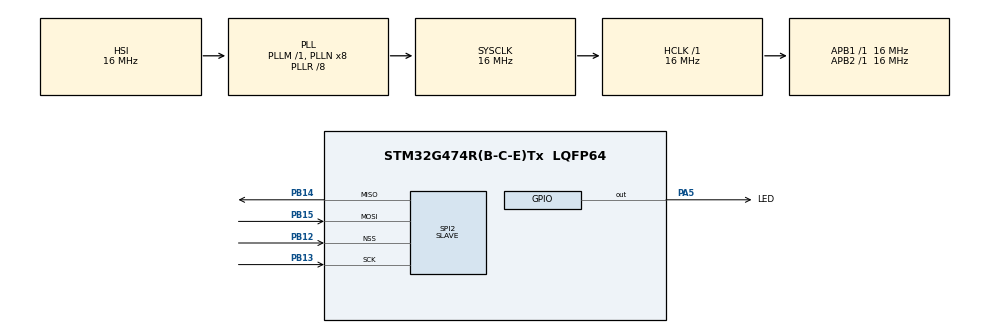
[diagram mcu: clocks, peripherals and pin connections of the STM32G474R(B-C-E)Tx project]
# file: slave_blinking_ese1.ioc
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Mcu.Family=STM32G4
Mcu.Name=STM32G474R(B-C-E)Tx
Mcu.Package=LQFP64
NVIC.PriorityGroup=NVIC_PRIORITYGROUP_4
PA5.GPIO_Label=LED
PA5.Signal=GPIO_Output
PB12.Mode=NSS_Signal_Hard_Input
PB12.Signal=SPI2_NSS
PB13.Mode=Full_Duplex_Slave
PB13.Signal=SPI2_SCK
PB14.Mode=Full_Duplex_Slave
PB14.Signal=SPI2_MISO
PB15.Mode=Full_Duplex_Slave
PB15.Signal=SPI2_MOSI
ProjectManager.HeapSize=0x200
ProjectManager.StackSize=0x400
ProjectManager.TargetToolchain=STM32CubeIDE
RCC.ADC12Freq_Value=16000000
RCC.ADC345Freq_Value=16000000
RCC.AHBFreq_Value=16000000
RCC.APB1Freq_Value=16000000
RCC.APB1TimFreq_Value=16000000
RCC.APB2Freq_Value=16000000
RCC.APB2TimFreq_Value=16000000
RCC.CortexFreq_Value=16000000
RCC.EXTERNAL_CLOCK_VALUE=12288000
RCC.HCLKFreq_Value=16000000
RCC.HSE_VALUE=24000000
RCC.HSI48_VALUE=48000000
RCC.HSI_VALUE=16000000
RCC.LSE_VALUE=32768
RCC.PLLR=RCC_PLLR_DIV8
RCC.RTCClockSelection=RCC_RTCCLKSOURCE_LSE
RCC.SYSCLKFreq_VALUE=16000000
RCC.SYSCLKSource=RCC_SYSCLKSOURCE_PLLCLK
RCC.USBFreq_Value=64000000
RCC.VCOOutputFreq_Value=128000000
SPI2.DataSize=SPI_DATASIZE_8BIT
SPI2.Direction=SPI_DIRECTION_2LINES
SPI2.Mode=SPI_MODE_SLAVE
SPI2.VirtualNSS=VM_NSSHARD
SPI2.VirtualType=VM_SLAVE
VP_SYS_VS_DBSignals.Mode=DisableDeadBatterySignals
board=NUCLEO-G474RE

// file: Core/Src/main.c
/* USER CODE BEGIN Header */
/**
  ******************************************************************************
  * @file           : main.c
  * @brief          : Main program body
  ******************************************************************************
  * @attention
  *
  * Copyright (c) 2026 STMicroelectronics.
  * All rights reserved.
  *
  * This software is licensed under terms that can be found in the LICENSE file
  * in the root directory of this software component.
  * If no LICENSE file comes with this software, it is provided AS-IS.
  *
  ******************************************************************************
  */
/* USER CODE END Header */
#include "main.h"
#include "spi.h"
#include "gpio.h"

void SystemClock_Config(void);

int main(void)
{

  /* USER CODE BEGIN 1 */
	uint8_t rx_msg=0;
  /* USER CODE END 1 */

  /* MCU Configuration--------------------------------------------------------*/

  /* Reset of all peripherals, Initializes the Flash interface and the Systick. */
  HAL_Init();

  /* Configure the system clock */
  SystemClock_Config();

  /* Initialize all configured peripherals */
  MX_GPIO_Init();
  MX_SPI2_Init();

  /* Infinite loop */
  while (1)
  {

    /* USER CODE BEGIN 3 */
	  HAL_SPI_Receive(&hspi2, &rx_msg, 1, HAL_MAX_DELAY);

	  switch(rx_msg){
	  case 0:
		  HAL_GPIO_WritePin(GPIOA, GPIO_PIN_5, GPIO_PIN_RESET);

		  break;
	  case 1:
		HAL_GPIO_WritePin(GPIOA, GPIO_PIN_5, GPIO_PIN_SET);
			break;
	  }

  }
  /* USER CODE END 3 */
}

void SystemClock_Config(void)
{
  RCC_OscInitTypeDef RCC_OscInitStruct = {0};
  RCC_ClkInitTypeDef RCC_ClkInitStruct = {0};

  /** Configure the main internal regulator output voltage
  */
  HAL_PWREx_ControlVoltageScaling(PWR_REGULATOR_VOLTAGE_SCALE1);

  /** Initializes the RCC Oscillators according to the specified parameters
  * in the RCC_OscInitTypeDef structure.
  */
  RCC_OscInitStruct.OscillatorType = RCC_OSCILLATORTYPE_HSI;
  RCC_OscInitStruct.HSIState = RCC_HSI_ON;
  RCC_OscInitStruct.HSICalibrationValue = RCC_HSICALIBRATION_DEFAULT;
  RCC_OscInitStruct.PLL.PLLState = RCC_PLL_ON;
  RCC_OscInitStruct.PLL.PLLSource = RCC_PLLSOURCE_HSI;
  RCC_OscInitStruct.PLL.PLLM = RCC_PLLM_DIV1;
  RCC_OscInitStruct.PLL.PLLN = 8;
  RCC_OscInitStruct.PLL.PLLP = RCC_PLLP_DIV2;
  RCC_OscInitStruct.PLL.PLLQ = RCC_PLLQ_DIV2;
  RCC_OscInitStruct.PLL.PLLR = RCC_PLLR_DIV8;
  if (HAL_RCC_OscConfig(&RCC_OscInitStruct) != HAL_OK)
  {
    Error_Handler();
  }

  /** Initializes the CPU, AHB and APB buses clocks
  */
  RCC_ClkInitStruct.ClockType = RCC_CLOCKTYPE_HCLK|RCC_CLOCKTYPE_SYSCLK
                              |RCC_CLOCKTYPE_PCLK1|RCC_CLOCKTYPE_PCLK2;
  RCC_ClkInitStruct.SYSCLKSource = RCC_SYSCLKSOURCE_PLLCLK;
  RCC_ClkInitStruct.AHBCLKDivider = RCC_SYSCLK_DIV1;
  RCC_ClkInitStruct.APB1CLKDivider = RCC_HCLK_DIV1;
  RCC_ClkInitStruct.APB2CLKDivider = RCC_HCLK_DIV1;

  if (HAL_RCC_ClockConfig(&RCC_ClkInitStruct, FLASH_LATENCY_0) != HAL_OK)
  {
    Error_Handler();
  }
}

void Error_Handler(void)
{
  __disable_irq();
  while (1)
  {
  }
}
